AUTOSAR XML (schema 4-2-2)
package /Components
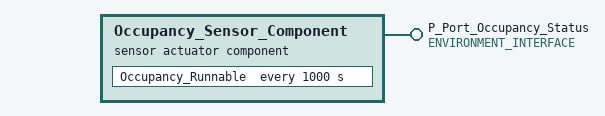
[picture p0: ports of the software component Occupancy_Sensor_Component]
  sensor actuator sw component type Occupancy_Sensor_Component
    provide port P_Port_Occupancy_Status: provided-interface=ENVIRONMENT_INTERFACE
    behavior Occupancy_Sensor_Behavior: handle-termination-and-restart=true
      init event Init_E: start-on-event=Occupancy_Runnable
      timing event Sample_Tick: start-on-event=Occupancy_Runnable, period=1000
      runnable Occupancy_Runnable: minimum-start-interval=100, can-be-invoked-concurrently=true, symbol=OCCUPANCY_STATUS_IREF
        data-receive-point-by-values:
          access OCCUPANCY_INPUT: accessed-variable=P_Port_Occupancy_Status.ENVIRONMENT_DATA
        data-send-points:
          access OCCUPANCY_OUTPUT: accessed-variable=R_Port_Occupancy_Status.ENVIRONMENT_DATA
